# NUC400_v1 register map
File version: 1.0
Registers are 32-bit, read-write, reset 0x0 unless marked. A register's access mark holds for its fields unless they carry their own. Offsets are from the block's base; [hi:lo] are bit positions; {n}, {i} and the like mark numbered series; 'fields as' and 'values as' point back to an identical list.

## EBI — EBI Register Map
Base 0x40010000
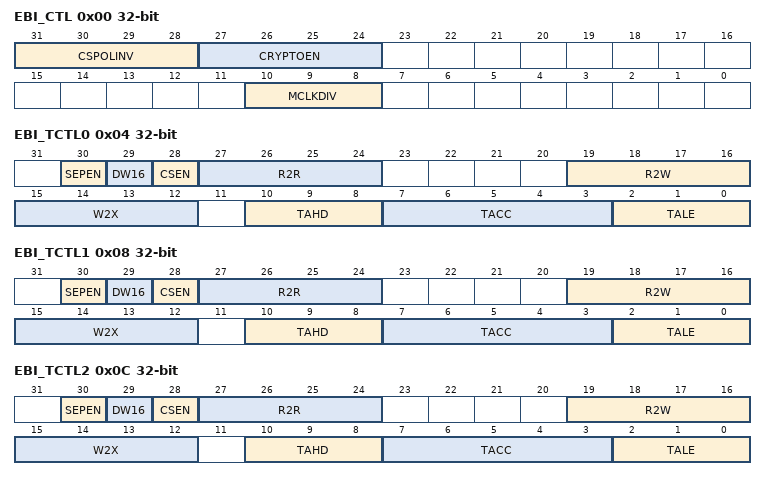
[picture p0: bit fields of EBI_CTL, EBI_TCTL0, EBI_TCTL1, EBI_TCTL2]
0x00 EBI_CTL — External Bus Interface General Control Register
  [31:28] CSPOLINV — Reverse Chip Select
    0=nCS (chip select active low); 1=CS (chip select active high)
  [27:24] CRYPTOEN — Encrypt/Decrypt Function Enable Bits (For 4 Individual Chip Select)
    0=Encrypt/Decrypt function Disabled; 1=Encrypt/Decrypt function Enabled
  [10:8] MCLKDIV — External Output Clock Divider. The frequency of EBI output clock is controlled by MCLKDIV as below: Note: Default value of output clock is HCLK/1
    0=HCLK/1; 1=HCLK/2; 2=HCLK/4; 3=HCLK/8. Default; 4=HCLK/16; 5=HCLK/32
0x04 EBI_TCTL0 — External Bus Interface Bank0 Timing Control Register
  [30] SEPEN — EBI Bank0 Address/Data Bus Separating Enable Bit
    0=Address/Data Bus Separating Disabled; 1=Address/Data Bus Separating Enabled
  [29] DW16 — EBI Bank0 Data Width 16-Bit. This bit defines if the data bus is 8-bit or 16-bit.
    0=EBI data width is 8-bit; 1=EBI data width is 16-bit
  [28] CSEN — EBI Bank0 Enable Bit. This bit is the functional enable bit for EBI.
    0=EBI function Disabled; 1=EBI function Enabled
  [27:24] R2R — Bank0 Idle State Cycle Between Read-Read. When read action is finish and next action is going to read, idle state is inserted and nCS[0] return to high if R2R is not zero.
  [19:16] R2W — Bank0 Idle State Cycle Between Read-Write. When read action is finish and next action is going to write, idle state is inserted and nCS[0] return to high if R2W is not zero.
  [15:12] W2X — Bank0 Idle State Cycle After Write. When write action is finish, idle state is inserted and nCS[0] return to high if W2X is not zero.
  [10:8] TAHD — EBI Bank0 Data Access Hold Time. TAHD define data access hold time (tAHD).
  [7:3] TACC — EBI Bank0 Data Access Time. TACC define data access time (tACC).
  [2:0] TALE — Bank0 Expand Time Of ALE. The ALE width (tALE) to latch the address can be controlled by TALE.
0x08 EBI_TCTL1 — External Bus Interface Bank1 Timing Control Register
  [30] SEPEN — EBI Bank1 Address/Data Bus Separating Enable Bit
    values as EBI_TCTL0.SEPEN
  [29] DW16 — EBI Bank1 Data Width 16-Bit. This bit defines if the data bus is 8-bit or 16-bit.
    0=EBI data width is 8-bit; 1=EBI data width is 16-bit
  [28] CSEN — EBI Bank1 Enable Bit. This bit is the functional enable bit for EBI.
    0=EBI function Disabled; 1=EBI function Enabled
  [27:24] R2R — Bank1 Idle State Cycle Between Read-Read. When read action is finish and next action is going to read, idle state is inserted and nCS[1] return to high if R2R is not zero.
  [19:16] R2W — Bank1 Idle State Cycle Between Read-Write. When read action is finish and next action is going to write, idle state is inserted and nCS[1] return to high if R2W is not zero.
  [15:12] W2X — Bank1 Idle State Cycle After Write. When write action is finish, idle state is inserted and nCS[1] return to high if W2X is not zero.
  [10:8] TAHD — EBI Bank1 Data Access Hold Time. TAHD define data access hold time (tAHD).
  [7:3] TACC — EBI Bank1 Data Access Time. TACC define data access time (tACC).
  [2:0] TALE — Bank1 Expand Time Of ALE. The ALE width (tALE) to latch the address can be controlled by TALE.
0x0C EBI_TCTL2 — External Bus Interface Bank2 Timing Control Register
  [30] SEPEN — EBI Bank2 Address/Data Bus Separating Enable Bit
    values as EBI_TCTL0.SEPEN
  [29] DW16 — EBI Bank2 Data Width 16-Bit. This bit defines if the data bus is 8-bit or 16-bit.
    0=EBI data width is 8-bit; 1=EBI data width is 16-bit
  [28] CSEN — EBI Bank2 Enable Bit. This bit is the functional enable bit for EBI.
    0=EBI function Disabled; 1=EBI function Enabled
  [27:24] R2R — Bank2 Idle State Cycle Between Read-Read. When read action is finish and next action is going to read, idle state is inserted and nCS[2] return to high if R2R is not 0.
  [19:16] R2W — Bank2 Idle State Cycle Between Read-Write. When read action is finish and next action is going to write, idle state is inserted and nCS[2] return to high if R2W is not 0.
  [15:12] W2X — Bank2 Idle State Cycle After Write. When write action is finish, idle state is inserted and nCS[2] return to high if W2X is not zero.
  [10:8] TAHD — EBI Bank2 Data Access Hold Time. TAHD define data access hold time (tAHD).
  [7:3] TACC — EBI Bank2 Data Access Time. TACC define data access time (tACC).
  [2:0] TALE — Bank2 Expand Time Of ALE. The ALE width (tALE) to latch the address can be controlled by TALE.
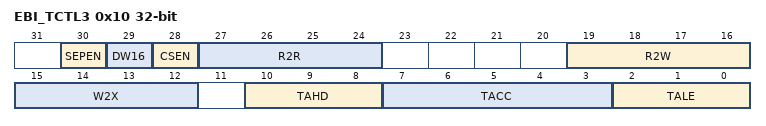
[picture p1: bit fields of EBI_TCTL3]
0x10 EBI_TCTL3 — External Bus Interface Bank3 Timing Control Register
  [30] SEPEN — EBI Bank3 Address/Data Bus Separating Enable Bit
    values as EBI_TCTL0.SEPEN
  [29] DW16 — EBI Bank3 Data Width 16-Bit. This bit defines if the data bus is 8-bit or 16-bit.
    0=EBI data width is 8-bit; 1=EBI data width is 16-bit
  [28] CSEN — EBI Bank3 Enable Bit. This bit is the functional enable bit for EBI.
    0=EBI function Disabled; 1=EBI function Enabled
  [27:24] R2R — Bank3 Idle State Cycle Between Read-Read. When read action is finish and next action is going to read, idle state is inserted and nCS[3] return to high if R2R is not zero. 0 : reserved.
  [19:16] R2W — Bank3 Idle State Cycle Between Read-Write. When read action is finish and next action is going to write, idle state is inserted and nCS[3] return to high if R2W is not zero. 0 : reserved.
  [15:12] W2X — Bank3 Idle State Cycle After Write. When write action is finish, idle state is inserted and nCS[3] return to high if W2X is not zero. 0 : reserved.
  [10:8] TAHD — EBI Bank3 Data Access Hold Time. TAHD define data access hold time (tAHD).
  [7:3] TACC — EBI Bank3 Data Access Time. TACC define data access time (tACC).
  [2:0] TALE — Bank3 Expand Time Of ALE. The ALE width (tALE) to latch the address can be controlled by TALE.
{0x14+4i} EBI_KEY{i} (i=0..3) — External Bus Interface Crypto Key Word {i}
  [31:0] KEY — Crypto Key Word {i} (key[{32i+31}:{32i}]).
